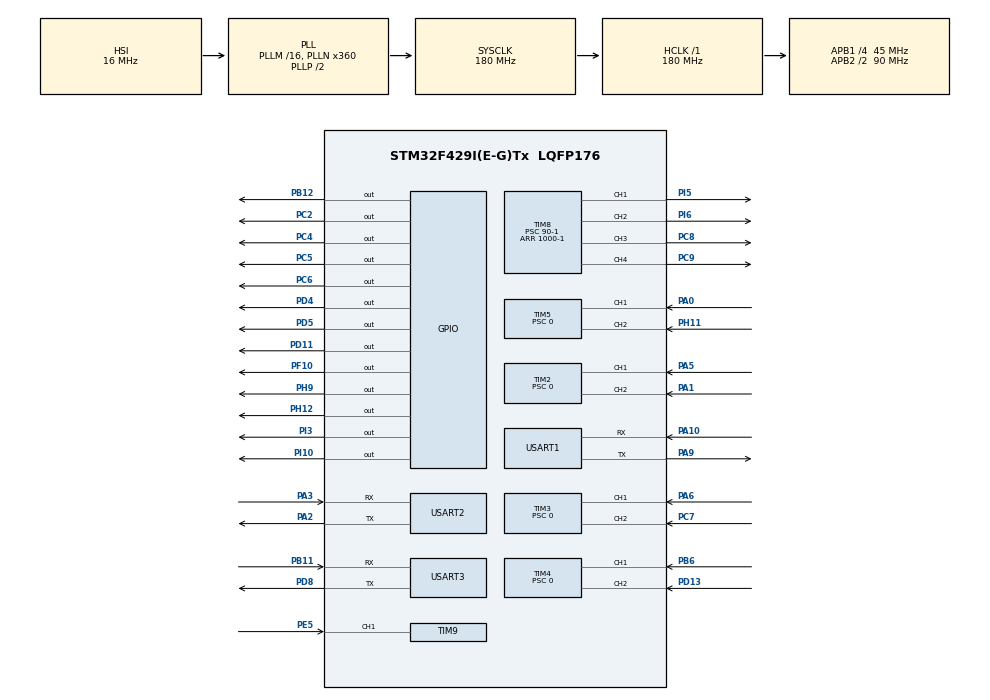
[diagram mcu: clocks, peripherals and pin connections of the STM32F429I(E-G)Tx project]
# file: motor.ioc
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Dma.Request0=USART3_TX
Dma.Request1=USART1_TX
Dma.Request2=USART2_RX
Dma.USART1_TX.1.Direction=DMA_MEMORY_TO_PERIPH
Dma.USART1_TX.1.FIFOMode=DMA_FIFOMODE_DISABLE
Dma.USART1_TX.1.Instance=DMA2_Stream7
Dma.USART1_TX.1.MemDataAlignment=DMA_MDATAALIGN_BYTE
Dma.USART1_TX.1.MemInc=DMA_MINC_ENABLE
Dma.USART1_TX.1.Mode=DMA_NORMAL
Dma.USART1_TX.1.PeriphDataAlignment=DMA_PDATAALIGN_BYTE
Dma.USART1_TX.1.PeriphInc=DMA_PINC_DISABLE
Dma.USART1_TX.1.Priority=DMA_PRIORITY_LOW
Dma.USART2_RX.2.Direction=DMA_PERIPH_TO_MEMORY
Dma.USART2_RX.2.FIFOMode=DMA_FIFOMODE_DISABLE
Dma.USART2_RX.2.Instance=DMA1_Stream5
Dma.USART2_RX.2.MemDataAlignment=DMA_MDATAALIGN_BYTE
Dma.USART2_RX.2.MemInc=DMA_MINC_ENABLE
Dma.USART2_RX.2.Mode=DMA_NORMAL
Dma.USART2_RX.2.PeriphDataAlignment=DMA_PDATAALIGN_BYTE
Dma.USART2_RX.2.PeriphInc=DMA_PINC_DISABLE
Dma.USART2_RX.2.Priority=DMA_PRIORITY_LOW
Dma.USART3_TX.0.Direction=DMA_MEMORY_TO_PERIPH
Dma.USART3_TX.0.FIFOMode=DMA_FIFOMODE_DISABLE
Dma.USART3_TX.0.Instance=DMA1_Stream3
Dma.USART3_TX.0.MemDataAlignment=DMA_MDATAALIGN_BYTE
Dma.USART3_TX.0.MemInc=DMA_MINC_ENABLE
Dma.USART3_TX.0.Mode=DMA_NORMAL
Dma.USART3_TX.0.PeriphDataAlignment=DMA_PDATAALIGN_BYTE
Dma.USART3_TX.0.PeriphInc=DMA_PINC_DISABLE
Dma.USART3_TX.0.Priority=DMA_PRIORITY_LOW
Mcu.Family=STM32F4
Mcu.Name=STM32F429I(E-G)Tx
Mcu.Package=LQFP176
NVIC.DMA1_Stream3_IRQn=true\:0\:0\:false\:false\:true\:false\:true
NVIC.DMA1_Stream5_IRQn=true\:0\:0\:false\:false\:true\:false\:true
NVIC.DMA2_Stream7_IRQn=true\:0\:0\:false\:false\:true\:false\:true
NVIC.PriorityGroup=NVIC_PRIORITYGROUP_4
NVIC.TIM1_BRK_TIM9_IRQn=true\:0\:0\:false\:false\:true\:true\:true
NVIC.TIM2_IRQn=true\:0\:0\:false\:false\:true\:true\:true
NVIC.TIM3_IRQn=true\:0\:0\:false\:false\:true\:true\:true
NVIC.TIM4_IRQn=true\:0\:0\:false\:false\:true\:true\:true
NVIC.TIM5_IRQn=true\:0\:0\:false\:false\:true\:true\:true
NVIC.USART1_IRQn=true\:0\:0\:false\:false\:true\:true\:true
NVIC.USART2_IRQn=true\:0\:0\:false\:false\:true\:true\:true
NVIC.USART3_IRQn=true\:0\:0\:false\:false\:true\:true\:true
PA0/WKUP.Signal=S_TIM5_CH1
PA1.Signal=S_TIM2_CH2
PA10.Mode=Asynchronous
PA10.Signal=USART1_RX
PA2.Mode=Asynchronous
PA2.Signal=USART2_TX
PA3.Mode=Asynchronous
PA3.Signal=USART2_RX
PA5.Signal=S_TIM2_CH1_ETR
PA6.Signal=S_TIM3_CH1
PA8.GPIO_PuPd=GPIO_PULLDOWN
PA8.Signal=S_TIM1_CH1
PA9.Mode=Asynchronous
PA9.Signal=USART1_TX
PB11.Mode=Asynchronous
PB11.Signal=USART3_RX
PB12.GPIO_PuPd=GPIO_PULLUP
PB12.Signal=GPIO_Output
PB6.Signal=S_TIM4_CH1
PC2.GPIO_PuPd=GPIO_PULLDOWN
PC2.Signal=GPIO_Output
PC4.GPIO_PuPd=GPIO_PULLUP
PC4.Signal=GPIO_Output
PC5.GPIO_PuPd=GPIO_PULLDOWN
PC5.Signal=GPIO_Output
PC6.GPIO_PuPd=GPIO_PULLUP
PC6.Signal=GPIO_Output
PC7.Signal=S_TIM3_CH2
PC8.Signal=S_TIM8_CH3
PC9.Signal=S_TIM8_CH4
PD11.GPIO_PuPd=GPIO_PULLDOWN
PD11.Signal=GPIO_Output
PD13.Signal=S_TIM4_CH2
PD4.Signal=GPIO_Output
PD5.GPIO_PuPd=GPIO_PULLUP
PD5.Signal=GPIO_Output
PD8.Mode=Asynchronous
PD8.Signal=USART3_TX
PE5.Signal=S_TIM9_CH1
PF10.GPIO_PuPd=GPIO_PULLDOWN
PF10.Signal=GPIO_Output
PH0/OSC_IN.Mode=HSE-External-Oscillator
PH0/OSC_IN.Signal=RCC_OSC_IN
PH1/OSC_OUT.Mode=HSE-External-Oscillator
PH1/OSC_OUT.Signal=RCC_OSC_OUT
PH11.Signal=S_TIM5_CH2
PH12.GPIO_ModeDefaultOutputPP=GPIO_MODE_OUTPUT_PP
PH12.GPIO_PuPd=GPIO_NOPULL
PH12.GPIO_Speed=GPIO_SPEED_FREQ_LOW
PH12.PinState=GPIO_PIN_RESET
PH12.Signal=GPIO_Output
PH9.GPIO_PuPd=GPIO_PULLUP
PH9.PinState=GPIO_PIN_SET
PH9.Signal=GPIO_Output
PI10.GPIO_PuPd=GPIO_PULLUP
PI10.PinState=GPIO_PIN_SET
PI10.Signal=GPIO_Output
PI3.GPIO_PuPd=GPIO_PULLDOWN
PI3.Signal=GPIO_Output
PI5.Signal=S_TIM8_CH1
PI6.Signal=S_TIM8_CH2
ProjectManager.HeapSize=0x200
ProjectManager.StackSize=0x400
ProjectManager.TargetToolchain=MDK-ARM V5
RCC.48MHZClocksFreq_Value=90000000
RCC.AHBFreq_Value=180000000
RCC.APB1CLKDivider=RCC_HCLK_DIV4
RCC.APB1Freq_Value=45000000
RCC.APB1TimFreq_Value=90000000
RCC.APB2CLKDivider=RCC_HCLK_DIV2
RCC.APB2Freq_Value=90000000
RCC.APB2TimFreq_Value=180000000
RCC.CortexFreq_Value=180000000
RCC.HCLKFreq_Value=180000000
RCC.HSE_VALUE=25000000
RCC.HSI_VALUE=16000000
RCC.LSE_VALUE=32768
RCC.PLLN=360
RCC.SYSCLKFreq_VALUE=180000000
RCC.SYSCLKSource=RCC_SYSCLKSOURCE_PLLCLK
RCC.VCOOutputFreq_Value=360000000
SH.S_TIM1_CH1.0=TIM1_CH1
SH.S_TIM2_CH1_ETR.0=TIM2_CH1,Encoder_Interface
SH.S_TIM2_CH2.0=TIM2_CH2,Encoder_Interface
SH.S_TIM3_CH1.0=TIM3_CH1,Encoder_Interface
SH.S_TIM3_CH2.0=TIM3_CH2,Encoder_Interface
SH.S_TIM4_CH1.0=TIM4_CH1,Encoder_Interface
SH.S_TIM4_CH2.0=TIM4_CH2,Encoder_Interface
SH.S_TIM5_CH1.0=TIM5_CH1,Encoder_Interface
SH.S_TIM5_CH2.0=TIM5_CH2,Encoder_Interface
SH.S_TIM8_CH1.0=TIM8_CH1,PWM Generation1 CH1
SH.S_TIM8_CH2.0=TIM8_CH2,PWM Generation2 CH2
SH.S_TIM8_CH3.0=TIM8_CH3,PWM Generation3 CH3
SH.S_TIM8_CH4.0=TIM8_CH4,PWM Generation4 CH4
SH.S_TIM9_CH1.0=TIM9_CH1,Input_Capture1_from_TI1
TIM2.EncoderMode=TIM_ENCODERMODE_TI12
TIM2.Period=65535
TIM2.Prescaler=0
TIM3.EncoderMode=TIM_ENCODERMODE_TI12
TIM3.Period=65535
TIM3.Prescaler=0
TIM4.EncoderMode=TIM_ENCODERMODE_TI12
TIM4.Period=65535
TIM4.Prescaler=0
TIM5.EncoderMode=TIM_ENCODERMODE_TI12
TIM5.Period=65535
TIM5.Prescaler=0
TIM8.Channel-PWM\ Generation1\ CH1=TIM_CHANNEL_1
TIM8.Channel-PWM\ Generation2\ CH2=TIM_CHANNEL_2
TIM8.Channel-PWM\ Generation3\ CH3=TIM_CHANNEL_3
TIM8.Channel-PWM\ Generation4\ CH4=TIM_CHANNEL_4
TIM8.Period=1000-1
TIM8.Prescaler=90-1
TIM9.Channel-Input_Capture1_from_TI1=TIM_CHANNEL_1
TIM9.Period=65535
TIM9.Prescaler=90
USART1.VirtualMode=VM_ASYNC
USART2.VirtualMode=VM_ASYNC
USART3.VirtualMode=VM_ASYNC
board=custom

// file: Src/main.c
/* USER CODE BEGIN Header */
/**
  ******************************************************************************
  * @file           : main.c
  * @brief          : Main program body
  ******************************************************************************
  * @attention
  *
  * <h2><center>&copy; Copyright (c) 2019 STMicroelectronics.
  * All rights reserved.</center></h2>
  *
  * This software component is licensed by ST under BSD 3-Clause license,
  * the "License"; You may not use this file except in compliance with the
  * License. You may obtain a copy of the License at:
  *                        opensource.org/licenses/BSD-3-Clause
  *
  ******************************************************************************
  */
/* USER CODE END Header */

#include "main.h"

/* USER CODE BEGIN Includes */
#include <user.h>
/* USER CODE END Includes */

/* USER CODE BEGIN PTD */
//600-2300,2000,700
/* USER CODE END PTD */

TIM_HandleTypeDef htim2;
TIM_HandleTypeDef htim3;
TIM_HandleTypeDef htim4;
TIM_HandleTypeDef htim5;
TIM_HandleTypeDef htim8;
TIM_HandleTypeDef htim9;

UART_HandleTypeDef huart1;
UART_HandleTypeDef huart2;
UART_HandleTypeDef huart3;
DMA_HandleTypeDef hdma_usart1_tx;
DMA_HandleTypeDef hdma_usart2_rx;
DMA_HandleTypeDef hdma_usart3_tx;

void SystemClock_Config(void);
static void MX_GPIO_Init(void);
static void MX_DMA_Init(void);
static void MX_GFXSIMULATOR_Init(void);
static void MX_TIM3_Init(void);
static void MX_USART3_UART_Init(void);
static void MX_USART1_UART_Init(void);
static void MX_TIM2_Init(void);
static void MX_USART2_UART_Init(void);
static void MX_TIM4_Init(void);
static void MX_TIM5_Init(void);
static void MX_TIM8_Init(void);
static void MX_TIM9_Init(void);

int main(void)
{

  /* MCU Configuration--------------------------------------------------------*/

  /* Reset of all peripherals, Initializes the Flash interface and the Systick. */
  HAL_Init();

  /* Configure the system clock */
  SystemClock_Config();

  /* Initialize all configured peripherals */
  MX_GPIO_Init();
  MX_DMA_Init();
  MX_GFXSIMULATOR_Init();
  MX_TIM3_Init();
  MX_USART3_UART_Init();
  MX_USART1_UART_Init();
  MX_TIM2_Init();
  MX_USART2_UART_Init();
  MX_TIM4_Init();
  MX_TIM5_Init();
  MX_TIM8_Init();
  MX_TIM9_Init();

  /* Infinite loop */
  while (1)
  {

    /* USER CODE BEGIN 3 */
		Robot_task();

  }
  /* USER CODE END 3 */
}

void SystemClock_Config(void)
{
  RCC_OscInitTypeDef RCC_OscInitStruct = {0};
  RCC_ClkInitTypeDef RCC_ClkInitStruct = {0};

  /** Configure the main internal regulator output voltage
  */
  __HAL_RCC_PWR_CLK_ENABLE();
  __HAL_PWR_VOLTAGESCALING_CONFIG(PWR_REGULATOR_VOLTAGE_SCALE1);
  /** Initializes the CPU, AHB and APB busses clocks
  */
  RCC_OscInitStruct.OscillatorType = RCC_OSCILLATORTYPE_HSI;
  RCC_OscInitStruct.HSIState = RCC_HSI_ON;
  RCC_OscInitStruct.HSICalibrationValue = RCC_HSICALIBRATION_DEFAULT;
  RCC_OscInitStruct.PLL.PLLState = RCC_PLL_ON;
  RCC_OscInitStruct.PLL.PLLSource = RCC_PLLSOURCE_HSI;
  RCC_OscInitStruct.PLL.PLLM = 16;
  RCC_OscInitStruct.PLL.PLLN = 360;
  RCC_OscInitStruct.PLL.PLLP = RCC_PLLP_DIV2;
  RCC_OscInitStruct.PLL.PLLQ = 4;
  if (HAL_RCC_OscConfig(&RCC_OscInitStruct) != HAL_OK)
  {
    Error_Handler();
  }
  /** Activate the Over-Drive mode
  */
  if (HAL_PWREx_EnableOverDrive() != HAL_OK)
  {
    Error_Handler();
  }
  /** Initializes the CPU, AHB and APB busses clocks
  */
  RCC_ClkInitStruct.ClockType = RCC_CLOCKTYPE_HCLK|RCC_CLOCKTYPE_SYSCLK
                              |RCC_CLOCKTYPE_PCLK1|RCC_CLOCKTYPE_PCLK2;
  RCC_ClkInitStruct.SYSCLKSource = RCC_SYSCLKSOURCE_PLLCLK;
  RCC_ClkInitStruct.AHBCLKDivider = RCC_SYSCLK_DIV1;
  RCC_ClkInitStruct.APB1CLKDivider = RCC_HCLK_DIV4;
  RCC_ClkInitStruct.APB2CLKDivider = RCC_HCLK_DIV2;

  if (HAL_RCC_ClockConfig(&RCC_ClkInitStruct, FLASH_LATENCY_5) != HAL_OK)
  {
    Error_Handler();
  }
}

static void MX_GFXSIMULATOR_Init(void)
{

}

static void MX_TIM2_Init(void)
{

  TIM_Encoder_InitTypeDef sConfig = {0};
  TIM_MasterConfigTypeDef sMasterConfig = {0};

  htim2.Instance = TIM2;
  htim2.Init.Prescaler = 0;
  htim2.Init.CounterMode = TIM_COUNTERMODE_UP;
  htim2.Init.Period = 65535;
  htim2.Init.ClockDivision = TIM_CLOCKDIVISION_DIV1;
  htim2.Init.AutoReloadPreload = TIM_AUTORELOAD_PRELOAD_DISABLE;
  sConfig.EncoderMode = TIM_ENCODERMODE_TI12;
  sConfig.IC1Polarity = TIM_ICPOLARITY_RISING;
  sConfig.IC1Selection = TIM_ICSELECTION_DIRECTTI;
  sConfig.IC1Prescaler = TIM_ICPSC_DIV1;
  sConfig.IC1Filter = 0;
  sConfig.IC2Polarity = TIM_ICPOLARITY_RISING;
  sConfig.IC2Selection = TIM_ICSELECTION_DIRECTTI;
  sConfig.IC2Prescaler = TIM_ICPSC_DIV1;
  sConfig.IC2Filter = 0;
  if (HAL_TIM_Encoder_Init(&htim2, &sConfig) != HAL_OK)
  {
    Error_Handler();
  }
  sMasterConfig.MasterOutputTrigger = TIM_TRGO_RESET;
  sMasterConfig.MasterSlaveMode = TIM_MASTERSLAVEMODE_DISABLE;
  if (HAL_TIMEx_MasterConfigSynchronization(&htim2, &sMasterConfig) != HAL_OK)
  {
    Error_Handler();
  }

}

static void MX_TIM3_Init(void)
{

  TIM_Encoder_InitTypeDef sConfig = {0};
  TIM_MasterConfigTypeDef sMasterConfig = {0};

  htim3.Instance = TIM3;
  htim3.Init.Prescaler = 0;
  htim3.Init.CounterMode = TIM_COUNTERMODE_UP;
  htim3.Init.Period = 65535;
  htim3.Init.ClockDivision = TIM_CLOCKDIVISION_DIV1;
  htim3.Init.AutoReloadPreload = TIM_AUTORELOAD_PRELOAD_DISABLE;
  sConfig.EncoderMode = TIM_ENCODERMODE_TI12;
  sConfig.IC1Polarity = TIM_ICPOLARITY_RISING;
  sConfig.IC1Selection = TIM_ICSELECTION_DIRECTTI;
  sConfig.IC1Prescaler = TIM_ICPSC_DIV1;
  sConfig.IC1Filter = 0;
  sConfig.IC2Polarity = TIM_ICPOLARITY_RISING;
  sConfig.IC2Selection = TIM_ICSELECTION_DIRECTTI;
  sConfig.IC2Prescaler = TIM_ICPSC_DIV1;
  sConfig.IC2Filter = 0;
  if (HAL_TIM_Encoder_Init(&htim3, &sConfig) != HAL_OK)
  {
    Error_Handler();
  }
  sMasterConfig.MasterOutputTrigger = TIM_TRGO_RESET;
  sMasterConfig.MasterSlaveMode = TIM_MASTERSLAVEMODE_DISABLE;
  if (HAL_TIMEx_MasterConfigSynchronization(&htim3, &sMasterConfig) != HAL_OK)
  {
    Error_Handler();
  }

}

static void MX_TIM4_Init(void)
{

  TIM_Encoder_InitTypeDef sConfig = {0};
  TIM_MasterConfigTypeDef sMasterConfig = {0};

  htim4.Instance = TIM4;
  htim4.Init.Prescaler = 0;
  htim4.Init.CounterMode = TIM_COUNTERMODE_UP;
  htim4.Init.Period = 65535;
  htim4.Init.ClockDivision = TIM_CLOCKDIVISION_DIV1;
  htim4.Init.AutoReloadPreload = TIM_AUTORELOAD_PRELOAD_DISABLE;
  sConfig.EncoderMode = TIM_ENCODERMODE_TI12;
  sConfig.IC1Polarity = TIM_ICPOLARITY_RISING;
  sConfig.IC1Selection = TIM_ICSELECTION_DIRECTTI;
  sConfig.IC1Prescaler = TIM_ICPSC_DIV1;
  sConfig.IC1Filter = 0;
  sConfig.IC2Polarity = TIM_ICPOLARITY_RISING;
  sConfig.IC2Selection = TIM_ICSELECTION_DIRECTTI;
  sConfig.IC2Prescaler = TIM_ICPSC_DIV1;
  sConfig.IC2Filter = 0;
  if (HAL_TIM_Encoder_Init(&htim4, &sConfig) != HAL_OK)
  {
    Error_Handler();
  }
  sMasterConfig.MasterOutputTrigger = TIM_TRGO_RESET;
  sMasterConfig.MasterSlaveMode = TIM_MASTERSLAVEMODE_DISABLE;
  if (HAL_TIMEx_MasterConfigSynchronization(&htim4, &sMasterConfig) != HAL_OK)
  {
    Error_Handler();
  }

}

static void MX_TIM5_Init(void)
{

  TIM_Encoder_InitTypeDef sConfig = {0};
  TIM_MasterConfigTypeDef sMasterConfig = {0};

  htim5.Instance = TIM5;
  htim5.Init.Prescaler = 0;
  htim5.Init.CounterMode = TIM_COUNTERMODE_UP;
  htim5.Init.Period = 65535;
  htim5.Init.ClockDivision = TIM_CLOCKDIVISION_DIV1;
  htim5.Init.AutoReloadPreload = TIM_AUTORELOAD_PRELOAD_DISABLE;
  sConfig.EncoderMode = TIM_ENCODERMODE_TI12;
  sConfig.IC1Polarity = TIM_ICPOLARITY_RISING;
  sConfig.IC1Selection = TIM_ICSELECTION_DIRECTTI;
  sConfig.IC1Prescaler = TIM_ICPSC_DIV1;
  sConfig.IC1Filter = 0;
  sConfig.IC2Polarity = TIM_ICPOLARITY_RISING;
  sConfig.IC2Selection = TIM_ICSELECTION_DIRECTTI;
  sConfig.IC2Prescaler = TIM_ICPSC_DIV1;
  sConfig.IC2Filter = 0;
  if (HAL_TIM_Encoder_Init(&htim5, &sConfig) != HAL_OK)
  {
    Error_Handler();
  }
  sMasterConfig.MasterOutputTrigger = TIM_TRGO_RESET;
  sMasterConfig.MasterSlaveMode = TIM_MASTERSLAVEMODE_DISABLE;
  if (HAL_TIMEx_MasterConfigSynchronization(&htim5, &sMasterConfig) != HAL_OK)
  {
    Error_Handler();
  }

}

static void MX_TIM8_Init(void)
{

  TIM_MasterConfigTypeDef sMasterConfig = {0};
  TIM_OC_InitTypeDef sConfigOC = {0};
  TIM_BreakDeadTimeConfigTypeDef sBreakDeadTimeConfig = {0};

  htim8.Instance = TIM8;
  htim8.Init.Prescaler = 90-1;
  htim8.Init.CounterMode = TIM_COUNTERMODE_UP;
  htim8.Init.Period = 1000-1;
  htim8.Init.ClockDivision = TIM_CLOCKDIVISION_DIV1;
  htim8.Init.RepetitionCounter = 0;
  htim8.Init.AutoReloadPreload = TIM_AUTORELOAD_PRELOAD_DISABLE;
  if (HAL_TIM_PWM_Init(&htim8) != HAL_OK)
  {
    Error_Handler();
  }
  sMasterConfig.MasterOutputTrigger = TIM_TRGO_RESET;
  sMasterConfig.MasterSlaveMode = TIM_MASTERSLAVEMODE_DISABLE;
  if (HAL_TIMEx_MasterConfigSynchronization(&htim8, &sMasterConfig) != HAL_OK)
  {
    Error_Handler();
  }
  sConfigOC.OCMode = TIM_OCMODE_PWM1;
  sConfigOC.Pulse = 0;
  sConfigOC.OCPolarity = TIM_OCPOLARITY_HIGH;
  sConfigOC.OCNPolarity = TIM_OCNPOLARITY_HIGH;
  sConfigOC.OCFastMode = TIM_OCFAST_DISABLE;
  sConfigOC.OCIdleState = TIM_OCIDLESTATE_RESET;
  sConfigOC.OCNIdleState = TIM_OCNIDLESTATE_RESET;
  if (HAL_TIM_PWM_ConfigChannel(&htim8, &sConfigOC, TIM_CHANNEL_1) != HAL_OK)
  {
    Error_Handler();
  }
  if (HAL_TIM_PWM_ConfigChannel(&htim8, &sConfigOC, TIM_CHANNEL_2) != HAL_OK)
  {
    Error_Handler();
  }
  if (HAL_TIM_PWM_ConfigChannel(&htim8, &sConfigOC, TIM_CHANNEL_3) != HAL_OK)
  {
    Error_Handler();
  }
  if (HAL_TIM_PWM_ConfigChannel(&htim8, &sConfigOC, TIM_CHANNEL_4) != HAL_OK)
  {
    Error_Handler();
  }
  sBreakDeadTimeConfig.OffStateRunMode = TIM_OSSR_DISABLE;
  sBreakDeadTimeConfig.OffStateIDLEMode = TIM_OSSI_DISABLE;
  sBreakDeadTimeConfig.LockLevel = TIM_LOCKLEVEL_OFF;
  sBreakDeadTimeConfig.DeadTime = 0;
  sBreakDeadTimeConfig.BreakState = TIM_BREAK_DISABLE;
  sBreakDeadTimeConfig.BreakPolarity = TIM_BREAKPOLARITY_HIGH;
  sBreakDeadTimeConfig.AutomaticOutput = TIM_AUTOMATICOUTPUT_DISABLE;
  if (HAL_TIMEx_ConfigBreakDeadTime(&htim8, &sBreakDeadTimeConfig) != HAL_OK)
  {
    Error_Handler();
  }
  HAL_TIM_MspPostInit(&htim8);

}

static void MX_TIM9_Init(void)
{

  TIM_IC_InitTypeDef sConfigIC = {0};

  htim9.Instance = TIM9;
  htim9.Init.Prescaler = 90;
  htim9.Init.CounterMode = TIM_COUNTERMODE_UP;
  htim9.Init.Period = 65535;
  htim9.Init.ClockDivision = TIM_CLOCKDIVISION_DIV1;
  htim9.Init.AutoReloadPreload = TIM_AUTORELOAD_PRELOAD_DISABLE;
  if (HAL_TIM_IC_Init(&htim9) != HAL_OK)
  {
    Error_Handler();
  }
  sConfigIC.ICPolarity = TIM_INPUTCHANNELPOLARITY_RISING;
  sConfigIC.ICSelection = TIM_ICSELECTION_DIRECTTI;
  sConfigIC.ICPrescaler = TIM_ICPSC_DIV1;
  sConfigIC.ICFilter = 0;
  if (HAL_TIM_IC_ConfigChannel(&htim9, &sConfigIC, TIM_CHANNEL_1) != HAL_OK)
  {
    Error_Handler();
  }

}

static void MX_USART1_UART_Init(void)
{

  huart1.Instance = USART1;
  huart1.Init.BaudRate = 115200;
  huart1.Init.WordLength = UART_WORDLENGTH_8B;
  huart1.Init.StopBits = UART_STOPBITS_1;
  huart1.Init.Parity = UART_PARITY_NONE;
  huart1.Init.Mode = UART_MODE_TX_RX;
  huart1.Init.HwFlowCtl = UART_HWCONTROL_NONE;
  huart1.Init.OverSampling = UART_OVERSAMPLING_16;
  if (HAL_UART_Init(&huart1) != HAL_OK)
  {
    Error_Handler();
  }

}

static void MX_USART2_UART_Init(void)
{

  huart2.Instance = USART2;
  huart2.Init.BaudRate = 115200;
  huart2.Init.WordLength = UART_WORDLENGTH_8B;
  huart2.Init.StopBits = UART_STOPBITS_1;
  huart2.Init.Parity = UART_PARITY_NONE;
  huart2.Init.Mode = UART_MODE_TX_RX;
  huart2.Init.HwFlowCtl = UART_HWCONTROL_NONE;
  huart2.Init.OverSampling = UART_OVERSAMPLING_16;
  if (HAL_UART_Init(&huart2) != HAL_OK)
  {
    Error_Handler();
  }

}

static void MX_USART3_UART_Init(void)
{

  huart3.Instance = USART3;
  huart3.Init.BaudRate = 115200;
  huart3.Init.WordLength = UART_WORDLENGTH_8B;
  huart3.Init.StopBits = UART_STOPBITS_1;
  huart3.Init.Parity = UART_PARITY_NONE;
  huart3.Init.Mode = UART_MODE_TX_RX;
  huart3.Init.HwFlowCtl = UART_HWCONTROL_NONE;
  huart3.Init.OverSampling = UART_OVERSAMPLING_16;
  if (HAL_UART_Init(&huart3) != HAL_OK)
  {
    Error_Handler();
  }

}

static void MX_DMA_Init(void)
{
  /* DMA controller clock enable */
  __HAL_RCC_DMA1_CLK_ENABLE();
  __HAL_RCC_DMA2_CLK_ENABLE();

  /* DMA interrupt init */
  /* DMA1_Stream3_IRQn interrupt configuration */
  HAL_NVIC_SetPriority(DMA1_Stream3_IRQn, 0, 0);
  HAL_NVIC_EnableIRQ(DMA1_Stream3_IRQn);
  /* DMA1_Stream5_IRQn interrupt configuration */
  HAL_NVIC_SetPriority(DMA1_Stream5_IRQn, 0, 0);
  HAL_NVIC_EnableIRQ(DMA1_Stream5_IRQn);
  /* DMA2_Stream7_IRQn interrupt configuration */
  HAL_NVIC_SetPriority(DMA2_Stream7_IRQn, 0, 0);
  HAL_NVIC_EnableIRQ(DMA2_Stream7_IRQn);

}

static void MX_GPIO_Init(void)
{
  GPIO_InitTypeDef GPIO_InitStruct = {0};

  /* GPIO Ports Clock Enable */
  __HAL_RCC_GPIOE_CLK_ENABLE();
  __HAL_RCC_GPIOI_CLK_ENABLE();
  __HAL_RCC_GPIOF_CLK_ENABLE();
  __HAL_RCC_GPIOH_CLK_ENABLE();
  __HAL_RCC_GPIOC_CLK_ENABLE();
  __HAL_RCC_GPIOA_CLK_ENABLE();
  __HAL_RCC_GPIOB_CLK_ENABLE();
  __HAL_RCC_GPIOD_CLK_ENABLE();

  /*Configure GPIO pin Output Level */
  HAL_GPIO_WritePin(GPIOI, GPIO_PIN_10, GPIO_PIN_SET);

  /*Configure GPIO pin Output Level */
  HAL_GPIO_WritePin(GPIOF, GPIO_PIN_10, GPIO_PIN_RESET);

  /*Configure GPIO pin Output Level */
  HAL_GPIO_WritePin(GPIOC, GPIO_PIN_2|GPIO_PIN_4|GPIO_PIN_5|GPIO_PIN_6, GPIO_PIN_RESET);

  /*Configure GPIO pin Output Level */
  HAL_GPIO_WritePin(GPIOH, GPIO_PIN_9, GPIO_PIN_SET);

  /*Configure GPIO pin Output Level */
  HAL_GPIO_WritePin(GPIOH, GPIO_PIN_12, GPIO_PIN_RESET);

  /*Configure GPIO pin Output Level */
  HAL_GPIO_WritePin(GPIOB, GPIO_PIN_12, GPIO_PIN_RESET);

  /*Configure GPIO pin Output Level */
  HAL_GPIO_WritePin(GPIOD, GPIO_PIN_11|GPIO_PIN_4|GPIO_PIN_5, GPIO_PIN_RESET);

  /*Configure GPIO pin Output Level */
  HAL_GPIO_WritePin(GPIOI, GPIO_PIN_3, GPIO_PIN_RESET);

  /*Configure GPIO pin : PI10 */
  GPIO_InitStruct.Pin = GPIO_PIN_10;
  GPIO_InitStruct.Mode = GPIO_MODE_OUTPUT_PP;
  GPIO_InitStruct.Pull = GPIO_PULLUP;
  GPIO_InitStruct.Speed = GPIO_SPEED_FREQ_LOW;
  HAL_GPIO_Init(GPIOI, &GPIO_InitStruct);

  /*Configure GPIO pin : PF10 */
  GPIO_InitStruct.Pin = GPIO_PIN_10;
  GPIO_InitStruct.Mode = GPIO_MODE_OUTPUT_PP;
  GPIO_InitStruct.Pull = GPIO_PULLDOWN;
  GPIO_InitStruct.Speed = GPIO_SPEED_FREQ_LOW;
  HAL_GPIO_Init(GPIOF, &GPIO_InitStruct);

  /*Configure GPIO pins : PC2 PC5 */
  GPIO_InitStruct.Pin = GPIO_PIN_2|GPIO_PIN_5;
  GPIO_InitStruct.Mode = GPIO_MODE_OUTPUT_PP;
  GPIO_InitStruct.Pull = GPIO_PULLDOWN;
  GPIO_InitStruct.Speed = GPIO_SPEED_FREQ_LOW;
  HAL_GPIO_Init(GPIOC, &GPIO_InitStruct);

  /*Configure GPIO pins : PC4 PC6 */
  GPIO_InitStruct.Pin = GPIO_PIN_4|GPIO_PIN_6;
  GPIO_InitStruct.Mode = GPIO_MODE_OUTPUT_PP;
  GPIO_InitStruct.Pull = GPIO_PULLUP;
  GPIO_InitStruct.Speed = GPIO_SPEED_FREQ_LOW;
  HAL_GPIO_Init(GPIOC, &GPIO_InitStruct);

  /*Configure GPIO pin : PH9 */
  GPIO_InitStruct.Pin = GPIO_PIN_9;
  GPIO_InitStruct.Mode = GPIO_MODE_OUTPUT_PP;
  GPIO_InitStruct.Pull = GPIO_PULLUP;
  GPIO_InitStruct.Speed = GPIO_SPEED_FREQ_LOW;
  HAL_GPIO_Init(GPIOH, &GPIO_InitStruct);

  /*Configure GPIO pin : PH12 */
  GPIO_InitStruct.Pin = GPIO_PIN_12;
  GPIO_InitStruct.Mode = GPIO_MODE_OUTPUT_PP;
  GPIO_InitStruct.Pull = GPIO_NOPULL;
  GPIO_InitStruct.Speed = GPIO_SPEED_FREQ_LOW;
  HAL_GPIO_Init(GPIOH, &GPIO_InitStruct);

  /*Configure GPIO pin : PB12 */
  GPIO_InitStruct.Pin = GPIO_PIN_12;
  GPIO_InitStruct.Mode = GPIO_MODE_OUTPUT_PP;
  GPIO_InitStruct.Pull = GPIO_PULLUP;
  GPIO_InitStruct.Speed = GPIO_SPEED_FREQ_LOW;
  HAL_GPIO_Init(GPIOB, &GPIO_InitStruct);

  /*Configure GPIO pin : PD11 */
  GPIO_InitStruct.Pin = GPIO_PIN_11;
  GPIO_InitStruct.Mode = GPIO_MODE_OUTPUT_PP;
  GPIO_InitStruct.Pull = GPIO_PULLDOWN;
  GPIO_InitStruct.Speed = GPIO_SPEED_FREQ_LOW;
  HAL_GPIO_Init(GPIOD, &GPIO_InitStruct);

  /*Configure GPIO pin : PA8 */
  GPIO_InitStruct.Pin = GPIO_PIN_8;
  GPIO_InitStruct.Mode = GPIO_MODE_AF_PP;
  GPIO_InitStruct.Pull = GPIO_PULLDOWN;
  GPIO_InitStruct.Speed = GPIO_SPEED_FREQ_LOW;
  GPIO_InitStruct.Alternate = GPIO_AF1_TIM1;
  HAL_GPIO_Init(GPIOA, &GPIO_InitStruct);

  /*Configure GPIO pin : PI3 */
  GPIO_InitStruct.Pin = GPIO_PIN_3;
  GPIO_InitStruct.Mode = GPIO_MODE_OUTPUT_PP;
  GPIO_InitStruct.Pull = GPIO_PULLDOWN;
  GPIO_InitStruct.Speed = GPIO_SPEED_FREQ_LOW;
  HAL_GPIO_Init(GPIOI, &GPIO_InitStruct);

  /*Configure GPIO pin : PD4 */
  GPIO_InitStruct.Pin = GPIO_PIN_4;
  GPIO_InitStruct.Mode = GPIO_MODE_OUTPUT_PP;
  GPIO_InitStruct.Pull = GPIO_NOPULL;
  GPIO_InitStruct.Speed = GPIO_SPEED_FREQ_LOW;
  HAL_GPIO_Init(GPIOD, &GPIO_InitStruct);

  /*Configure GPIO pin : PD5 */
  GPIO_InitStruct.Pin = GPIO_PIN_5;
  GPIO_InitStruct.Mode = GPIO_MODE_OUTPUT_PP;
  GPIO_InitStruct.Pull = GPIO_PULLUP;
  GPIO_InitStruct.Speed = GPIO_SPEED_FREQ_LOW;
  HAL_GPIO_Init(GPIOD, &GPIO_InitStruct);

}

void Error_Handler(void)
{
}

/************************ (C) COPYRIGHT STMicroelectronics *****END OF FILE****/
